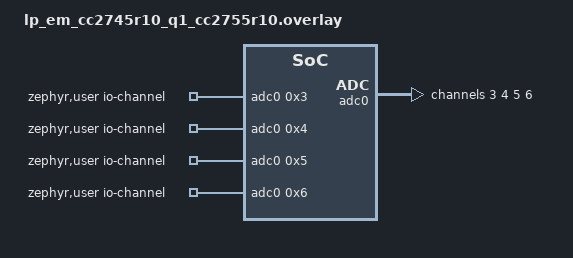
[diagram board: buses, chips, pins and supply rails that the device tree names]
/*
 * Copyright (c) 2025 Texas Instruments Incorporated
 * Copyright (c) 2024 BayLibre, SAS
 *
 * SPDX-License-Identifier: Apache-2.0
 */

#include <zephyr/dt-bindings/adc/adc.h>

/ {
	zephyr,user {
		io-channels = <&adc0 0x3>, <&adc0 0x4>, <&adc0 0x5>, <&adc0 0x6>;
	};

	aliases {
		adc0 = &adc0;
	};
};

&adc0 {
	status = "okay";

	#address-cells = <1>;
	#size-cells = <0>;

	channel@3 {
		reg = <3>;
		zephyr,gain = "ADC_GAIN_1";
		zephyr,reference = "ADC_REF_VDD_1";
		zephyr,vref-mv = <3300>;
		//zephyr,acquisition-time = <ADC_ACQ_TIME(ADC_ACQ_TIME_TICKS, 5)>;
		zephyr,acquisition-time = <ADC_ACQ_TIME(ADC_ACQ_TIME_MICROSECONDS, 20)>;
		//zephyr,acquisition-time = <ADC_ACQ_TIME(ADC_ACQ_TIME_NANOSECONDS, 210)>;
		zephyr,resolution = <12>;
	};

	channel@4 {
		reg = <4>;
		zephyr,gain = "ADC_GAIN_1";
		zephyr,reference = "ADC_REF_VDD_1";
		zephyr,vref-mv = <3300>;
		//zephyr,acquisition-time = <ADC_ACQ_TIME(ADC_ACQ_TIME_TICKS, 5)>;
		zephyr,acquisition-time = <ADC_ACQ_TIME(ADC_ACQ_TIME_MICROSECONDS, 20)>;
		//zephyr,acquisition-time = <ADC_ACQ_TIME(ADC_ACQ_TIME_NANOSECONDS, 210)>;
		zephyr,resolution = <12>;
	};

	channel@5 {
		reg = <5>;
		zephyr,gain = "ADC_GAIN_1";
		zephyr,reference = "ADC_REF_VDD_1";
		zephyr,vref-mv = <3300>;
		//zephyr,acquisition-time = <ADC_ACQ_TIME(ADC_ACQ_TIME_TICKS, 5)>;
		zephyr,acquisition-time = <ADC_ACQ_TIME(ADC_ACQ_TIME_MICROSECONDS, 20)>;
		//zephyr,acquisition-time = <ADC_ACQ_TIME(ADC_ACQ_TIME_NANOSECONDS, 210)>;
		zephyr,resolution = <12>;
	};

	channel@6 {
		reg = <6>;
		zephyr,gain = "ADC_GAIN_1";
		zephyr,reference = "ADC_REF_VDD_1";
		zephyr,vref-mv = <3300>;
		//zephyr,acquisition-time = <ADC_ACQ_TIME(ADC_ACQ_TIME_TICKS, 5)>;
		zephyr,acquisition-time = <ADC_ACQ_TIME(ADC_ACQ_TIME_MICROSECONDS, 20)>;
		//zephyr,acquisition-time = <ADC_ACQ_TIME(ADC_ACQ_TIME_NANOSECONDS, 210)>;
		zephyr,resolution = <12>;
	};
};
